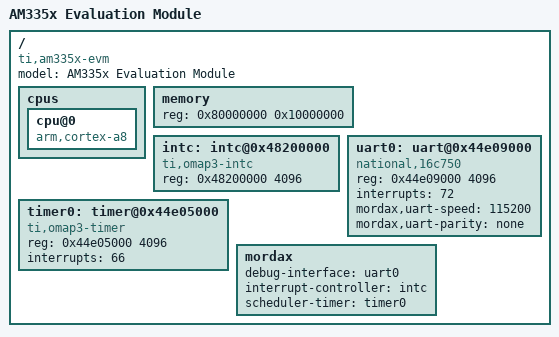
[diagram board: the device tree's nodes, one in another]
/*       Mordax Microkernel device tree file for the AM335x EVM        */
/*   (c) Kristian Klomsten Skordal 2013 <kristian.skordal@gmail.com>   */
/* Report bugs and issues on <http://github.com/skordal/mordax/issues> */

/dts-v1/;

/ {
	compatible = "ti,am335x-evm";
	model = "AM335x Evaluation Module";

	#address-cells = <1>;
	#size-cells = <1>;

	cpus {
		cpu@0 {
			compatible = "arm,cortex-a8";
		};
	};

	memory {
		device_type = "memory";
		reg = <0x80000000 0x10000000>; /* 256 Mb */
	};

	intc: intc@0x48200000 {
		compatible = "ti,omap3-intc";
		reg = <0x48200000 4096>;
	};

	uart0: uart@0x44e09000 {
		compatible = "national,16c750";
		reg = <0x44e09000 4096>;
		interrupts = <72>;

		mordax,uart-speed = <115200>;
		mordax,uart-parity = "none";
	};

	timer0: timer@0x44e05000 {
		compatible = "ti,omap3-timer";
		reg = <0x44e05000 4096>;
		interrupts = <66>;
	};

	mordax {
		debug-interface = <&uart0>;
		interrupt-controller = <&intc>;
		scheduler-timer = <&timer0>;
	};
};



